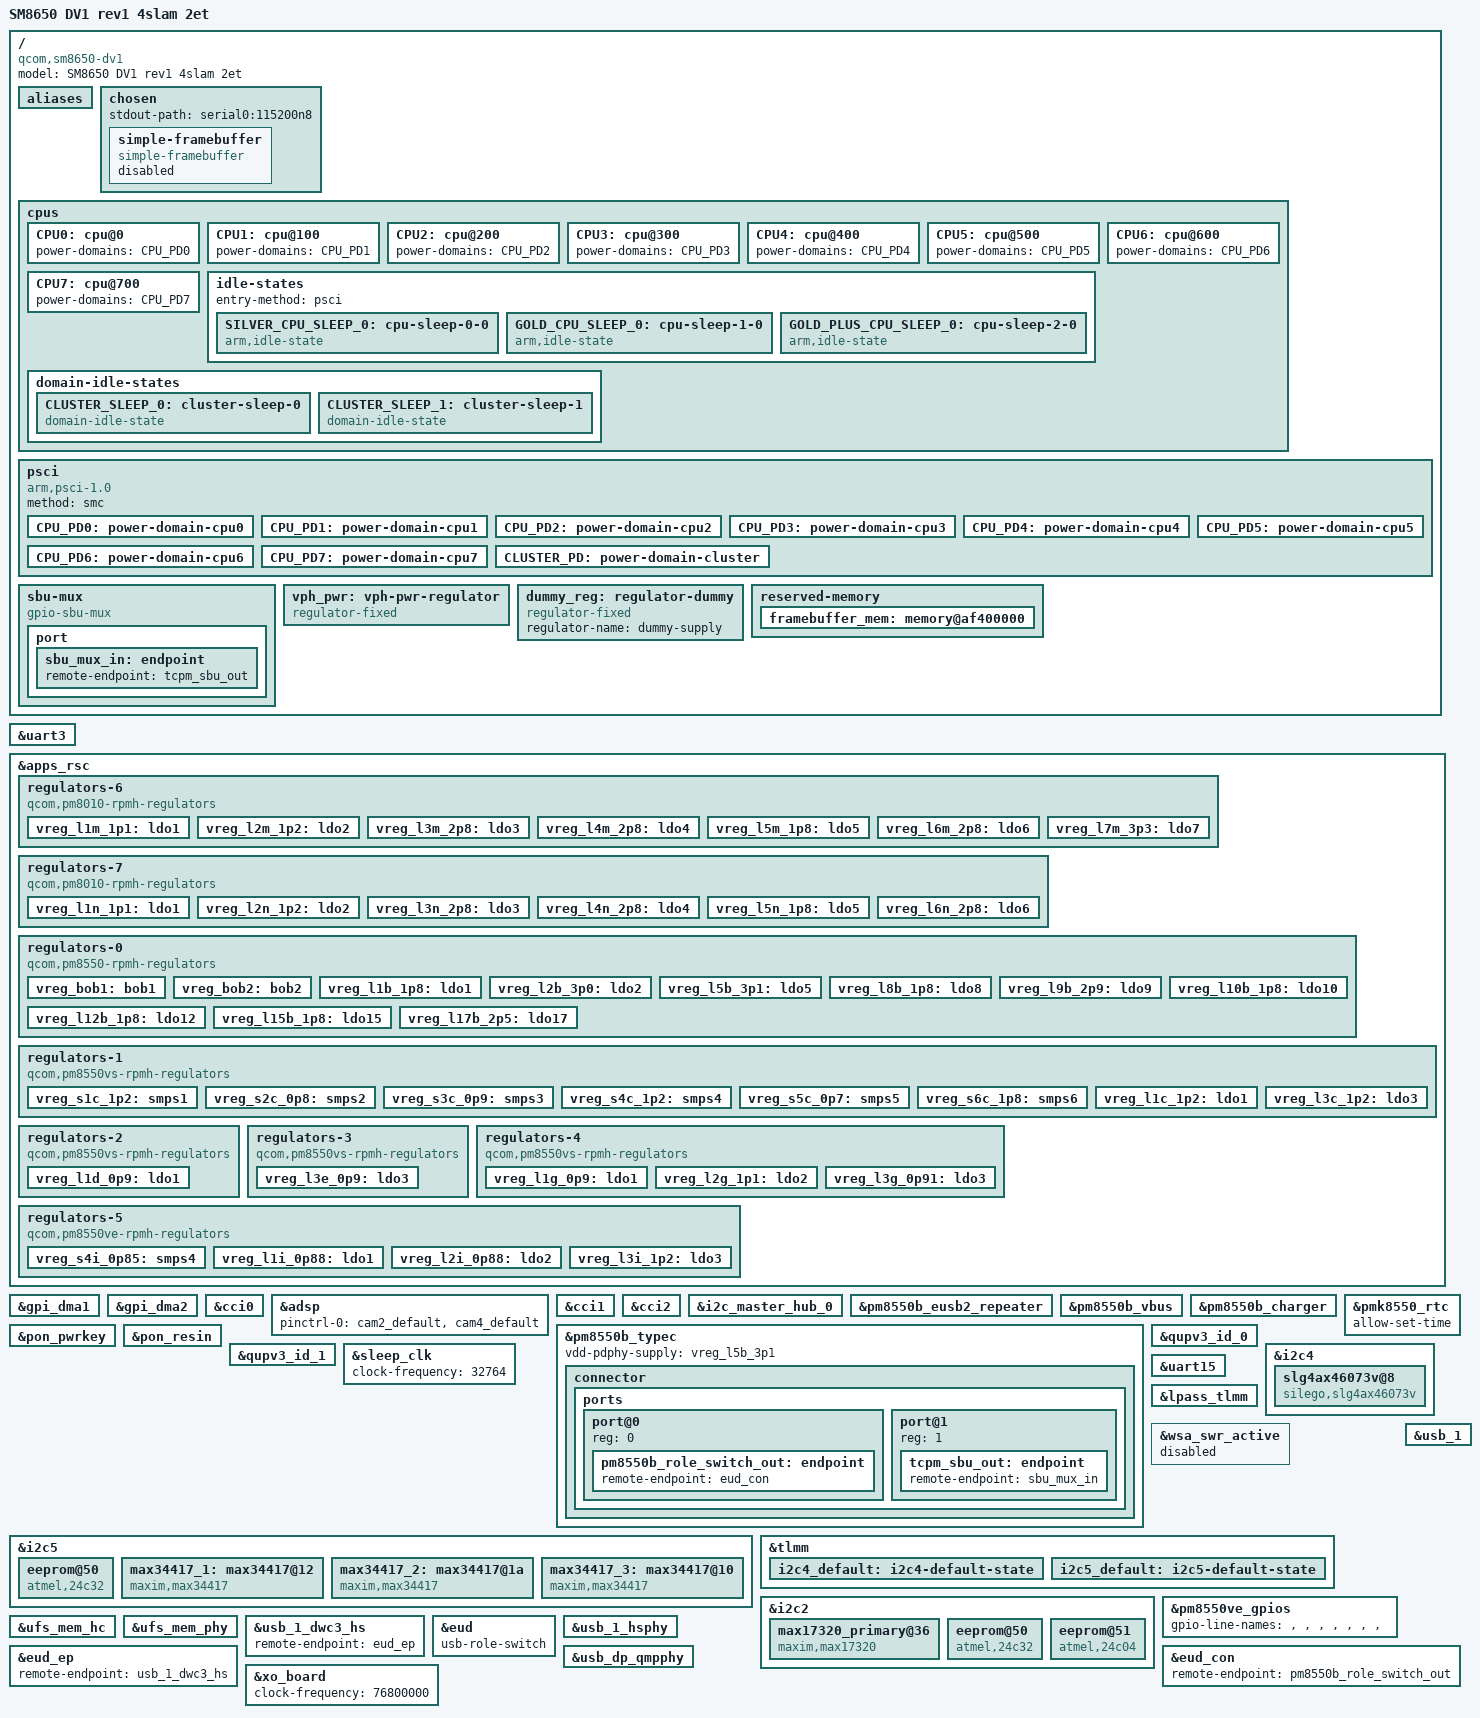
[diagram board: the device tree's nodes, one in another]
/dts-v1/;

#include <dt-bindings/leds/common.h>
#include <dt-bindings/regulator/qcom,rpmh-regulator.h>
#include <dt-bindings/phy/phy.h>
#include "dt-bindings/usb/pd.h"
#include "sm8650.dtsi"
#include "pm8010.dtsi"
#include "pm8550.dtsi"
#include "pm8550b.dtsi"
#include "pm8550vs.dtsi"
#define PMK8550VE_SID 8
#include "pm8550ve.dtsi"
#include "pmk8550.dtsi"
#include "sm8650-el2.dtsi"

/ {
	model = "SM8650 DV1 rev1 4slam 2et";
	compatible = "qcom,sm8650-dv1", "qcom,sm8650";

	aliases {
		serial0 = &uart15;
		serial1 = &uart14;
		serial2 = &uart3;
	};

	chosen {
		stdout-path = "serial0:115200n8";

		simple-framebuffer {
			compatible = "simple-framebuffer";
			width = <4320>;
			height = <2160>;
			stride = <(4320 * 4)>;
			format = "a8r8g8b8";
			memory-region = <&framebuffer_mem>;
			status = "disabled";
		};
	};	

	cpus {

		CPU0: cpu@0 {
			power-domains = <&CPU_PD0>;
			power-domain-names = "psci";
		};

		CPU1: cpu@100 {
			power-domains = <&CPU_PD1>;
			power-domain-names = "psci";
		};

		CPU2: cpu@200 {
			power-domains = <&CPU_PD2>;
			power-domain-names = "psci";
		};

		CPU3: cpu@300 {
			power-domains = <&CPU_PD3>;
			power-domain-names = "psci";
		};

		CPU4: cpu@400 {
			power-domains = <&CPU_PD4>;
			power-domain-names = "psci";
		};

		CPU5: cpu@500 {
			power-domains = <&CPU_PD5>;
			power-domain-names = "psci";
		};

		CPU6: cpu@600 {
			power-domains = <&CPU_PD6>;
			power-domain-names = "psci";
		};

		CPU7: cpu@700 {
			power-domains = <&CPU_PD7>;
			power-domain-names = "psci";
		};

		idle-states {
			entry-method = "psci";

			SILVER_CPU_SLEEP_0: cpu-sleep-0-0 {
				compatible = "arm,idle-state";
				idle-state-name = "silver-rail-power-collapse";
				arm,psci-suspend-param = <0x40000004>;
				entry-latency-us = <550>;
				exit-latency-us = <750>;
				min-residency-us = <6700>;
				local-timer-stop;
			};

			GOLD_CPU_SLEEP_0: cpu-sleep-1-0 {
				compatible = "arm,idle-state";
				idle-state-name = "gold-rail-power-collapse";
				arm,psci-suspend-param = <0x40000004>;
				entry-latency-us = <600>;
				exit-latency-us = <1300>;
				min-residency-us = <8136>;
				local-timer-stop;
			};

			GOLD_PLUS_CPU_SLEEP_0: cpu-sleep-2-0 {
				compatible = "arm,idle-state";
				idle-state-name = "gold-plus-rail-power-collapse";
				arm,psci-suspend-param = <0x40000004>;
				entry-latency-us = <500>;
				exit-latency-us = <1350>;
				min-residency-us = <7480>;
				local-timer-stop;
			};
		};

		domain-idle-states {
			CLUSTER_SLEEP_0: cluster-sleep-0 {
				compatible = "domain-idle-state";
				arm,psci-suspend-param = <0x41000044>;
				entry-latency-us = <750>;
				exit-latency-us = <2350>;
				min-residency-us = <9144>;
			};

			CLUSTER_SLEEP_1: cluster-sleep-1 {
				compatible = "domain-idle-state";
				arm,psci-suspend-param = <0x4100c344>;
				entry-latency-us = <2800>;
				exit-latency-us = <4400>;
				min-residency-us = <10150>;
			};
		};
	};

	psci {
		compatible = "arm,psci-1.0";
		method = "smc";

		CPU_PD0: power-domain-cpu0 {
			#power-domain-cells = <0>;
			power-domains = <&CLUSTER_PD>;
			domain-idle-states = <&SILVER_CPU_SLEEP_0>;
		};

		CPU_PD1: power-domain-cpu1 {
			#power-domain-cells = <0>;
			power-domains = <&CLUSTER_PD>;
			domain-idle-states = <&SILVER_CPU_SLEEP_0>;
		};

		CPU_PD2: power-domain-cpu2 {
			#power-domain-cells = <0>;
			power-domains = <&CLUSTER_PD>;
			domain-idle-states = <&SILVER_CPU_SLEEP_0>;
		};

		CPU_PD3: power-domain-cpu3 {
			#power-domain-cells = <0>;
			power-domains = <&CLUSTER_PD>;
			domain-idle-states = <&GOLD_CPU_SLEEP_0>;
		};

		CPU_PD4: power-domain-cpu4 {
			#power-domain-cells = <0>;
			power-domains = <&CLUSTER_PD>;
			domain-idle-states = <&GOLD_CPU_SLEEP_0>;
		};

		CPU_PD5: power-domain-cpu5 {
			#power-domain-cells = <0>;
			power-domains = <&CLUSTER_PD>;
			domain-idle-states = <&GOLD_CPU_SLEEP_0>;
		};

		CPU_PD6: power-domain-cpu6 {
			#power-domain-cells = <0>;
			power-domains = <&CLUSTER_PD>;
			domain-idle-states = <&GOLD_CPU_SLEEP_0>;
		};

		CPU_PD7: power-domain-cpu7 {
			#power-domain-cells = <0>;
			power-domains = <&CLUSTER_PD>;
			domain-idle-states = <&GOLD_PLUS_CPU_SLEEP_0>;
		};

		CLUSTER_PD: power-domain-cluster {
			#power-domain-cells = <0>;
			domain-idle-states = <&CLUSTER_SLEEP_0>,
					     <&CLUSTER_SLEEP_1>;
		};
	};

	sbu-mux {
		compatible = "gpio-sbu-mux";

		enable-gpios = <&tlmm 86 GPIO_ACTIVE_LOW>;
		select-gpios = <&tlmm 82 GPIO_ACTIVE_HIGH>;

		mode-switch;
		orientation-switch;

		port {
			sbu_mux_in: endpoint {
				remote-endpoint = <&tcpm_sbu_out>;
			};
		};

		// XXX: needs VREG_L05B_3P1, VREG_BOB2
	};

	vph_pwr: vph-pwr-regulator {
		compatible = "regulator-fixed";

		regulator-name = "vph_pwr";
		regulator-min-microvolt = <3700000>;
		regulator-max-microvolt = <3700000>;

		regulator-always-on;
		regulator-boot-on;
	};



	dummy_reg: regulator-dummy {
		compatible = "regulator-fixed";
		regulator-name = "dummy-supply";
	};

	reserved-memory {
                ranges;

                framebuffer_mem: memory@af400000 {
			reg = <0 0xaf400000 0 0x03000000>;
                        no-map;
                };
        };

};

&uart3 {
	status = "okay";
};


&apps_rsc {
    regulators-6 {
        vdd-l6-supply = <&vreg_bob2>;
    };
    regulators-7 {
        vdd-l6-supply = <&vreg_bob2>;
    };
};


&apps_rsc {
	regulators-0 {
		compatible = "qcom,pm8550-rpmh-regulators";

		vdd-bob1-supply = <&vph_pwr>;
		vdd-bob2-supply = <&vph_pwr>;
		vdd-l1-l4-l10-supply = <&vreg_s6c_1p8>;
		vdd-l2-l13-l14-supply = <&vreg_bob1>;
		vdd-l3-supply = <&vreg_s1c_1p2>;
		vdd-l5-l16-supply = <&vreg_bob1>;
		vdd-l8-l9-supply = <&vreg_bob1>;
		vdd-l12-supply = <&vreg_s6c_1p8>;
		vdd-l15-supply = <&vreg_s6c_1p8>;
		vdd-l17-supply = <&vreg_bob2>;

		qcom,pmic-id = "b";

		vreg_bob1: bob1 {
			regulator-name = "vreg_bob1";
			regulator-min-microvolt = <3296000>; // note: min is 3008000, init is 3296000
			regulator-max-microvolt = <3960000>;
			regulator-initial-mode = <RPMH_REGULATOR_MODE_HPM>;
		};

		vreg_bob2: bob2 {
			regulator-name = "vreg_bob2";
			regulator-min-microvolt = <2720000>; // note: min is 2704000, init is 2720000
			regulator-max-microvolt = <3008000>;
			regulator-initial-mode = <RPMH_REGULATOR_MODE_HPM>;

			regulator-always-on; // XXX USB HS, SBU MUX
		};

		vreg_l1b_1p8: ldo1 {
			regulator-name = "vreg_l1b_1p8";
			regulator-min-microvolt = <1800000>;
			regulator-max-microvolt = <1800000>;
			regulator-initial-mode = <RPMH_REGULATOR_MODE_HPM>;

			regulator-always-on; // XXX sensors
		};

		vreg_l2b_3p0: ldo2 {
			regulator-name = "vreg_l2b_3p0";
			regulator-min-microvolt = <3008000>;
			regulator-max-microvolt = <3008000>;
			regulator-initial-mode = <RPMH_REGULATOR_MODE_HPM>;

			regulator-always-on; // XXX sensors
		};

		vreg_l5b_3p1: ldo5 {
			regulator-name = "vreg_l5b_3p1";
			regulator-min-microvolt = <3104000>;
			regulator-max-microvolt = <3104000>;
			regulator-initial-mode = <RPMH_REGULATOR_MODE_HPM>;
			regulator-allow-set-load;
			regulator-allowed-modes = <RPMH_REGULATOR_MODE_LPM
						   RPMH_REGULATOR_MODE_HPM>;
			regulator-always-on; // XXX SBU MUX
		};

		vreg_l8b_1p8: ldo8 {
			regulator-name = "vreg_l8b_1p8";
			regulator-min-microvolt = <1800000>;
			regulator-max-microvolt = <1800000>;
			regulator-initial-mode = <RPMH_REGULATOR_MODE_HPM>;
			regulator-allow-set-load;
			regulator-allowed-modes = <RPMH_REGULATOR_MODE_LPM
						   RPMH_REGULATOR_MODE_HPM>;
		};

		vreg_l9b_2p9: ldo9 {
			regulator-name = "vreg_l9b_2p9";
			regulator-min-microvolt = <2960000>;
			regulator-max-microvolt = <2960000>;
			regulator-initial-mode = <RPMH_REGULATOR_MODE_HPM>;
			regulator-allow-set-load;
			regulator-allowed-modes = <RPMH_REGULATOR_MODE_LPM
						   RPMH_REGULATOR_MODE_HPM>;
		};

		vreg_l10b_1p8: ldo10 {
			regulator-name = "vreg_l10b_1p8";
			regulator-min-microvolt = <1800000>;
			regulator-max-microvolt = <1800000>;
			regulator-initial-mode = <RPMH_REGULATOR_MODE_HPM>;

			regulator-always-on; // XXX DMIC
		};

		vreg_l12b_1p8: ldo12 {
			regulator-name = "vreg_l12b_1p8";
			regulator-min-microvolt = <1800000>;
			regulator-max-microvolt = <1800000>;
			regulator-initial-mode = <RPMH_REGULATOR_MODE_HPM>;
			regulator-allow-set-load;
			regulator-allowed-modes = <RPMH_REGULATOR_MODE_LPM
						   RPMH_REGULATOR_MODE_HPM>;
		};

		vreg_l15b_1p8: ldo15 {
			regulator-name = "vreg_l15b_1p8";
			regulator-min-microvolt = <1800000>;
			regulator-max-microvolt = <1800000>;
			regulator-initial-mode = <RPMH_REGULATOR_MODE_HPM>;
			regulator-allow-set-load;
			regulator-allowed-modes = <RPMH_REGULATOR_MODE_LPM
						   RPMH_REGULATOR_MODE_HPM>;
			regulator-always-on; // XXX: 1.8V pull ups
		};

		vreg_l17b_2p5: ldo17 {
			regulator-name = "vreg_l17b_2p5";
			regulator-min-microvolt = <2504000>;
			regulator-max-microvolt = <2504000>;
			regulator-initial-mode = <RPMH_REGULATOR_MODE_HPM>;
			regulator-allow-set-load;
			regulator-allowed-modes = <RPMH_REGULATOR_MODE_LPM
						   RPMH_REGULATOR_MODE_HPM>;
		};
	};

	regulators-1 {
		compatible = "qcom,pm8550vs-rpmh-regulators";

		vdd-l1-supply = <&vreg_s1c_1p2>;
		vdd-l3-supply = <&vreg_s1c_1p2>;
		vdd-s1-supply = <&vph_pwr>;
		vdd-s2-supply = <&vph_pwr>;
		vdd-s3-supply = <&vph_pwr>;
		vdd-s4-supply = <&vph_pwr>;
		vdd-s5-supply = <&vph_pwr>;
		vdd-s6-supply = <&vph_pwr>;

		qcom,pmic-id = "c";

		vreg_s1c_1p2: smps1 {
			regulator-name = "vreg_s1c_1p2";
			regulator-min-microvolt = <1224000>;
			regulator-max-microvolt = <1348000>;
			// init 1256000
			regulator-initial-mode = <RPMH_REGULATOR_MODE_HPM>;

			regulator-always-on; // USB, UFS?
		};

		vreg_s2c_0p8: smps2 {
			regulator-name = "vreg_s2c_0p8";
			regulator-min-microvolt = <500000>;
			regulator-max-microvolt = <1036000>;
			// init 852000
			regulator-initial-mode = <RPMH_REGULATOR_MODE_HPM>;
		};

		vreg_s3c_0p9: smps3 {
			regulator-name = "vreg_s3c_0p9";
			regulator-min-microvolt = <904000>;
			regulator-max-microvolt = <1064000>;
			// init 976000
			regulator-initial-mode = <RPMH_REGULATOR_MODE_HPM>;
		};

		vreg_s4c_1p2: smps4 {
			regulator-name = "vreg_s4c_1p2";
			regulator-min-microvolt = <1200000>;
			regulator-max-microvolt = <1280000>;
			// init 1224000
			regulator-initial-mode = <RPMH_REGULATOR_MODE_HPM>;
		};

		vreg_s5c_0p7: smps5 {
			regulator-name = "vreg_s5c_0p7";
			regulator-min-microvolt = <300000>;
			regulator-max-microvolt = <900000>;
			// init 752000
			regulator-initial-mode = <RPMH_REGULATOR_MODE_HPM>;
		};

		vreg_s6c_1p8: smps6 {
			regulator-name = "vreg_s6c_1p8";
			regulator-min-microvolt = <1856000>;
			regulator-max-microvolt = <2000000>;
			// init 1856000
			regulator-initial-mode = <RPMH_REGULATOR_MODE_HPM>;
		};

		vreg_l1c_1p2: ldo1 {
			regulator-name = "vreg_l1c_1p2";
			regulator-min-microvolt = <1200000>; // note: min 1100000
			regulator-max-microvolt = <1200000>;
			regulator-initial-mode = <RPMH_REGULATOR_MODE_HPM>;
		};

		vreg_l3c_1p2: ldo3 {
			regulator-name = "vreg_l3c_1p2";
			regulator-min-microvolt = <1200000>;
			regulator-max-microvolt = <1200000>;
			regulator-initial-mode = <RPMH_REGULATOR_MODE_HPM>;
			regulator-allow-set-load;
			regulator-allowed-modes = <RPMH_REGULATOR_MODE_LPM
						   RPMH_REGULATOR_MODE_HPM>;
			regulator-always-on; // XXX: 1.2V pull ups
		};
	};

	regulators-2 {
		compatible = "qcom,pm8550vs-rpmh-regulators";
		qcom,pmic-id = "d";

		vdd-l1-supply = <&vreg_s3c_0p9>;

		vreg_l1d_0p9: ldo1 {
			regulator-name = "vreg_l1d_0p9";
			regulator-min-microvolt = <912000>; // note: min 880000
			regulator-max-microvolt = <920000>;
			regulator-initial-mode = <RPMH_REGULATOR_MODE_HPM>;
			regulator-allow-set-load;
			regulator-allowed-modes = <RPMH_REGULATOR_MODE_LPM
						   RPMH_REGULATOR_MODE_HPM>;
		};
	};

	regulators-3 {
		compatible = "qcom,pm8550vs-rpmh-regulators";

		vdd-l3-supply = <&vreg_s3c_0p9>;

		qcom,pmic-id = "e";

		vreg_l3e_0p9: ldo3 {
			regulator-name = "vreg_l3e_0p9";
			regulator-min-microvolt = <880000>;
			regulator-max-microvolt = <920000>;
			regulator-initial-mode = <RPMH_REGULATOR_MODE_HPM>;
			regulator-allow-set-load;
			regulator-allowed-modes = <RPMH_REGULATOR_MODE_LPM
						   RPMH_REGULATOR_MODE_HPM>;
		};
	};

	regulators-4 {
		compatible = "qcom,pm8550vs-rpmh-regulators";

		vdd-l1-supply = <&vreg_s3c_0p9>;
		vdd-l2-supply = <&vreg_s1c_1p2>;
		vdd-l3-supply = <&vreg_s3c_0p9>;

		qcom,pmic-id = "g";

		vreg_l1g_0p9: ldo1 {
			regulator-name = "vreg_l1g_0p9";
			regulator-min-microvolt = <912000>;
			regulator-max-microvolt = <920000>;
			regulator-initial-mode = <RPMH_REGULATOR_MODE_HPM>;
			// QLINK ?
		};

		vreg_l2g_1p1: ldo2 {
			regulator-name = "vreg_l2g_1p1";
			regulator-min-microvolt = <1104000>;
			regulator-max-microvolt = <1104000>;
			regulator-initial-mode = <RPMH_REGULATOR_MODE_HPM>;
		};

		vreg_l3g_0p91: ldo3 {
			regulator-name = "vreg_l3g_0p91";
			regulator-min-microvolt = <880000>;
			regulator-max-microvolt = <912000>;
			regulator-initial-mode = <RPMH_REGULATOR_MODE_HPM>;
		};
	};

	regulators-5 {
		compatible = "qcom,pm8550ve-rpmh-regulators";

		vdd-l1-supply = <&vreg_s3c_0p9>;
		vdd-l2-supply = <&vreg_s3c_0p9>;
		vdd-l3-supply = <&vreg_s1c_1p2>;
		vdd-s4-supply = <&vph_pwr>;

		qcom,pmic-id = "i";

		vreg_s4i_0p85: smps4 {
			regulator-name = "vreg_s4i_0p85";
			regulator-min-microvolt = <852000>;
			regulator-max-microvolt = <1004000>;
			// init 852000
			regulator-initial-mode = <RPMH_REGULATOR_MODE_HPM>;
		};

		vreg_l1i_0p88: ldo1 {
			regulator-name = "vreg_l1i_0p88";
			regulator-min-microvolt = <880000>;
			regulator-max-microvolt = <912000>;
			regulator-initial-mode = <RPMH_REGULATOR_MODE_HPM>;
			regulator-allow-set-load;
			regulator-allowed-modes = <RPMH_REGULATOR_MODE_LPM
						   RPMH_REGULATOR_MODE_HPM>;
		};

		vreg_l2i_0p88: ldo2 {
			regulator-name = "vreg_l2i_0p88";
			regulator-min-microvolt = <880000>;
			regulator-max-microvolt = <912000>;
			regulator-initial-mode = <RPMH_REGULATOR_MODE_HPM>;
			regulator-allow-set-load;
			regulator-allowed-modes = <RPMH_REGULATOR_MODE_LPM
						   RPMH_REGULATOR_MODE_HPM>;

			//regulator-always-on; // CSI PHY
		};

		vreg_l3i_1p2: ldo3 {
			regulator-name = "vreg_l3i_1p2";
			regulator-min-microvolt = <1200000>;
			regulator-max-microvolt = <1200000>;
			regulator-initial-mode = <RPMH_REGULATOR_MODE_HPM>;
			regulator-allow-set-load;
			regulator-allowed-modes = <RPMH_REGULATOR_MODE_LPM
						   RPMH_REGULATOR_MODE_HPM>;

			//regulator-always-on; // CSI PHY
		};
	};

	regulators-6 {
		compatible = "qcom,pm8010-rpmh-regulators";
		qcom,pmic-id = "m";

		vdd-l1-l2-supply = <&vreg_s1c_1p2>;
		vdd-l3-l4-supply = <&vreg_bob2>;
		vdd-l5-supply = <&vreg_s6c_1p8>;
		vdd-l6-supply = <&vreg_bob1>;
		vdd-l7-supply = <&vreg_bob1>;

		vreg_l1m_1p1: ldo1 {
			regulator-name = "vreg_l1m_1p1";
			regulator-min-microvolt = <1104000>;
			regulator-max-microvolt = <1104000>;
			regulator-initial-mode = <RPMH_REGULATOR_MODE_HPM>;
			regulator-allow-set-load;
			regulator-allowed-modes = <RPMH_REGULATOR_MODE_LPM
						   RPMH_REGULATOR_MODE_HPM>;
		};

		vreg_l2m_1p2: ldo2 {
			regulator-name = "vreg_l2m_1p2";
			regulator-min-microvolt = <1200000>;
			regulator-max-microvolt = <1200000>;
			regulator-initial-mode = <RPMH_REGULATOR_MODE_HPM>;
			regulator-allow-set-load;
			regulator-allowed-modes = <RPMH_REGULATOR_MODE_LPM
						   RPMH_REGULATOR_MODE_HPM>;
		};

		vreg_l3m_2p8: ldo3 {
			regulator-name = "vreg_l3m_2p8";
			regulator-min-microvolt = <2800000>;
			regulator-max-microvolt = <2800000>;
			regulator-initial-mode = <RPMH_REGULATOR_MODE_HPM>;
		};

		vreg_l4m_2p8: ldo4 {
			regulator-name = "vreg_l4m_2p8";
			regulator-min-microvolt = <2800000>;
			regulator-max-microvolt = <2800000>;
			regulator-initial-mode = <RPMH_REGULATOR_MODE_HPM>;
		};

		vreg_l5m_1p8: ldo5 {
			regulator-name = "vreg_l5m_1p8";
			regulator-min-microvolt = <1800000>;
			regulator-max-microvolt = <1800000>;
			regulator-initial-mode = <RPMH_REGULATOR_MODE_HPM>;
		};

		vreg_l6m_2p8: ldo6 {
			regulator-name = "vreg_l6m_2p8";
			regulator-min-microvolt = <2800000>;
			regulator-max-microvolt = <2800000>;
			regulator-initial-mode = <RPMH_REGULATOR_MODE_HPM>;
		};

		vreg_l7m_3p3: ldo7 {
			regulator-name = "vreg_l7m_3p3";
			regulator-min-microvolt = <3304000>;
			regulator-max-microvolt = <3304000>;
			regulator-initial-mode = <RPMH_REGULATOR_MODE_HPM>;

			regulator-always-on;
		};
	};

	regulators-7 {
		compatible = "qcom,pm8010-rpmh-regulators";
		qcom,pmic-id = "n";

		vdd-l1-l2-supply = <&vreg_s1c_1p2>;
		vdd-l3-l4-supply = <&vreg_bob2>;
		vdd-l5-supply = <&vreg_s6c_1p8>;
		vdd-l6-supply = <&vreg_bob1>;

		vreg_l1n_1p1: ldo1 {
			regulator-name = "vreg_l1n_1p1";
			regulator-min-microvolt = <1104000>;
			regulator-max-microvolt = <1104000>;
			regulator-initial-mode = <RPMH_REGULATOR_MODE_HPM>;
			regulator-allow-set-load;
			regulator-allowed-modes = <RPMH_REGULATOR_MODE_LPM
						   RPMH_REGULATOR_MODE_HPM>;
		};

		vreg_l2n_1p2: ldo2 {
			regulator-name = "vreg_l2n_1p2";
			regulator-min-microvolt = <1200000>;
			regulator-max-microvolt = <1200000>;
			regulator-initial-mode = <RPMH_REGULATOR_MODE_HPM>;
			regulator-allow-set-load;
			regulator-allowed-modes = <RPMH_REGULATOR_MODE_LPM
						   RPMH_REGULATOR_MODE_HPM>;
		};

		vreg_l3n_2p8: ldo3 {
			regulator-name = "vreg_l3n_2p8";
			regulator-min-microvolt = <2800000>;
			regulator-max-microvolt = <2800000>;
			regulator-initial-mode = <RPMH_REGULATOR_MODE_HPM>;
		};

		vreg_l4n_2p8: ldo4 {
			regulator-name = "vreg_l4n_2p8";
			regulator-min-microvolt = <2800000>;
			regulator-max-microvolt = <2800000>;
			regulator-initial-mode = <RPMH_REGULATOR_MODE_HPM>;
		};

		vreg_l5n_1p8: ldo5 {
			regulator-name = "vreg_l5n_1p8";
			regulator-min-microvolt = <1800000>;
			regulator-max-microvolt = <1800000>;
			regulator-initial-mode = <RPMH_REGULATOR_MODE_HPM>;
		};

		vreg_l6n_2p8: ldo6 {
			regulator-name = "vreg_l6n_2p8";
			regulator-min-microvolt = <2800000>;
			regulator-max-microvolt = <2800000>;
			regulator-initial-mode = <RPMH_REGULATOR_MODE_HPM>;
		};
	};
};

&gpi_dma1 {
	status = "okay";
};

&gpi_dma2 {
	status = "okay";
};

&cci0 {
	status = "okay";
};

// ADSP controls eye tracking cameras
&adsp {
	// AON CAM ADSP TEST: gpio102/104 to mclk function
	pinctrl-names = "default";
	pinctrl-0 = <&cam2_default &cam4_default>;
};

&cci1 {
	pinctrl-0 = <&cci1_0_default>;
	pinctrl-1 = <&cci1_0_sleep>;
	status = "okay";
};

&cci2 {
	status = "okay";
};


// Master Hub required for Hub 7 and 8
&i2c_master_hub_0 {
	status = "okay";
};


&pm8550b_eusb2_repeater {
	vdd18-supply = <&vreg_l15b_1p8>;
	vdd3-supply = <&vreg_l5b_3p1>;
};

&pm8550b_vbus {
	status = "okay";
};

&pm8550b_typec {
	status = "okay";

	vdd-pdphy-supply = <&vreg_l5b_3p1>;

	connector {
		power-role = "dual";
		data-role = "dual";
		try-power-role = "sink";
		
		source-pdos = <PDO_FIXED(5000, 3000, PDO_FIXED_DUAL_ROLE | PDO_FIXED_DATA_SWAP | PDO_FIXED_USB_COMM)>;
		
		//sink-pdos needs to have 5000mV entry first otherwise will not probe
		sink-pdos = <PDO_FIXED(5000, 3000, PDO_FIXED_DUAL_ROLE | PDO_FIXED_DATA_SWAP | PDO_FIXED_USB_COMM)>,
                    <PDO_FIXED(9000, 3000, PDO_FIXED_DUAL_ROLE | PDO_FIXED_DATA_SWAP | PDO_FIXED_USB_COMM)>,
                    <PDO_FIXED(12000, 3000, PDO_FIXED_DUAL_ROLE | PDO_FIXED_DATA_SWAP | PDO_FIXED_USB_COMM)>,
                    <PDO_FIXED(15000, 3000, PDO_FIXED_DUAL_ROLE | PDO_FIXED_DATA_SWAP | PDO_FIXED_USB_COMM)>;

		op-sink-microwatt = <15000000>;

		ports {
			#address-cells = <1>;
			#size-cells = <0>;

			port@0 {
				reg = <0>;

				pm8550b_role_switch_out: endpoint {
					remote-endpoint = <&eud_con>;
				};
			};

			port@1 {
				reg = <1>;

				tcpm_sbu_out: endpoint {
					remote-endpoint = <&sbu_mux_in>;
				};
			};

#if 0
			port@2 {
				reg = <2>;

				dp_mode_out: endpoint {
					remote-endpoint = <&dp_mode>;
				};
			};


			port@1 {
				reg = <1>;

				pm8550b_typec_mux_out: endpoint {
					remote-endpoint = <&usb_1_qmpphy_typec_mux_in>;
				};
			};
#endif
		};
	};

};

&pm8550b_charger {
	status = "okay";
	qph1-charge-current-max = <1200000>;
	qph2-charge-current-max = <2700000>;
};

&pmk8550_rtc {
	status = "okay";
	allow-set-time;
};

&pon_pwrkey {
	status = "okay";
};

&pon_resin {
	linux,code = <KEY_VOLUMEDOWN>;
	disable-wake-source;
	status = "okay";
};


&qupv3_id_0 {
	status = "okay";
};

&qupv3_id_1 {
	status = "okay";
};



&sleep_clk {
	clock-frequency = <32764>;
};



&i2c4 {
	status = "okay";
	
    /* FAN_I2C */
	slg4ax46073v@8 {
		compatible = "silego,slg4ax46073v";
		reg = <0x08>;
		#address-cells = <1>;
		#size-cells = <0>;

		//vdd-fan-1-supply = <&VBATT_2S>; not modeled in dts
		fan-alert-gpios = <&tlmm 174 GPIO_ACTIVE_HIGH>;
		en-gpio = <&tlmm 138 GPIO_ACTIVE_HIGH>;
		// bp pin removed in ev1

		status = "okay";
	};

};

&i2c5 {
	status = "okay";

};

&uart15 {
	status = "okay";
};

&lpass_tlmm {
	status = "okay";
};

// Disable Soundwire
&wsa_swr_active {
	status = "disabled";
};

&tlmm {
	// TODO verify reserved pins for 8650
	// qcom,gpios-reserved = <36 37 38 39>;
	gpio-line-names =
		// GPIO000 - GPIO015
		"",  "",  "",  "",  "",  "",  "",  "fpga_rst",  "",  "",  "",  "nrf_time_sync",  "",  "",  "",  "",
		// GPIO016 - GPIO031
		"",  "",  "",  "",  "",  "",  "",  "",  "",  "",  "",  "",  "",  "",  "",  "",
		// GPIO032 - GPIO047
		"",  "",  "",  "fpga_spi_cs",  "",  "",  "",  "fpga_crst",  "",  "",  "",  "",  "",  "",  "",  "",
		// GPIO048 - GPIO063
		"",  "",  "nrf_swdio",  "nrf_swclk",  "",  "",  "",  "",  "fpga_cam0_strobe",  "fpga_cam1_strobe",  "",  "",  "",  "",  "",  "",
		// GPIO064 - GPIO079
		"",  "",  "",  "",  "",  "",  "",  "",  "",  "",  "",  "",  "",  "",  "",  "",
		// GPIO080 - GPIO095
		"",  "",  "",  "",  "",  "",  "",  "",  "",  "",  "",  "",  "",  "",  "",  "",
		// GPIO096 - GPIO111
		"",  "",  "",  "",  "",  "",  "",  "",  "",  "",  "",  "",  "",  "",  "fpga_cam1_frame_sync",  "",
		// GPIO112 - GPIO127
		"",  "",  "",  "",  "",  "",  "",  "",  "",  "",  "",  "",  "fpga_cam0_frame_sync",  "",  "",  "",
		// GPIO128 - GPIO143
		"",  "",  "",  "",  "",  "",  "",  "",  "",  "",  "",  "",  "",  "",  "",  "",
		// GPIO144 - GPIO159
		"",  "",  "",  "",  "",  "",  "",  "",  "",  "",  "",  "fpga_cdone",  "",  "",  "fpga_cready",  "",
		// GPIO160 - GPIO175
		"",  "",  "te2_left",  "",  "nrf_reset",  "",  "",  "",  "",  "",  "",  "",  "",  "",  "",  "",
		// GPIO176 - GPIO189
		"",  "",  "te2_right",  "",  "", "", "", "", "", "", "", "", "", "";
};

&i2c5 {
    // BOOT EEPROM
    eeprom@50 {
        compatible  = "atmel,24c32";
        status      = "okay";
        label		= "core_eeprom";
        reg         = <0x50>;
		pagesize    = <32>;
		size        = <4096>;
		address-width = <16>;
        wp-gpios = <&tlmm 78 GPIO_ACTIVE_HIGH>;
        vcc-supply  = <&vreg_l15b_1p8>;
    };

    max34417_1: max34417@12 {
        compatible = "maxim,max34417";
        reg = <0x12>;
        maxim,sense-resistor = <1>;
        vdd-supply = <&vreg_l2b_3p0>;
        vio-supply = <&vreg_l15b_1p8>;
        status = "okay";

        // CH 1 : Kryo APC0 Cores
        // CH 2 : Kryo APC2 Cores
        // CH 3 : Kryo APC1 Cores
        // CH 4 : Tensor Processor – NSP1
        // Note: both 1.8 and 3.0V rails are always on for other sensors
    };

    max34417_2: max34417@1a {
        compatible = "maxim,max34417";
        reg = <0x1a>;
        maxim,sense-resistor = <1>;
        vdd-supply = <&vreg_l2b_3p0>;
        vio-supply = <&vreg_l15b_1p8>;
        status = "okay";

        // CH 1 : GFX Power
        // CH 2 : Tensor Processor – NSP2
        // CH 3 : Bob Power
        // CH 4 : Unused
        // Note: both 1.8 and 3.0V rails are always on for other sensors
    };

    // TODO enable verr ( varies based on common mode range )
    max34417_3: max34417@10 {
        compatible = "maxim,max34417";
        reg = <0x10>;
        maxim,sense-resistor = <1>;
        vdd-supply = <&vreg_l2b_3p0>;
        vio-supply = <&vreg_l15b_1p8>;
        status = "okay";

        // CH 1 : VPH
        // CH 2 : S6C ~1.9V Subregulation
        // CH 3 : S3C ~1.3V Subregulation
        // CH 4 : S1C ~1V Subregulation
        // Note: both 1.8 and 3.0V rails are always on for other sensors
    }; 
};

// Custom Connector I2C ( Paddle Card )
&i2c2 {
	status = "okay";

	// Southgate/Northgate Primary Built In Battery
	max17320_primary@36 {
		compatible  = "maxim,max17320";
		status		= "okay";
		reg         = <0x36>;
		nvm_reg     = /bits/ 8 <0x0b>;
		rsense      = <25>;      /* 100's of microOhms */
	};

	// Southgate/Northgate Secondary Hotswap Battery
	// NOTE This is handled dynamically by northgate_hotswap driver
	// max17320_hotswap@76 {
	//	compatible  = "maxim,max17320";
	//	status		= "okay";
	//	reg         = <0x76>;
	//	nvm_reg     = /bits/ 8 <0x4b>;
	//	rsense      = <25>;      /* 100's of microOhms */
	// };

    // PADDLE EEPROM
    eeprom@50 {
        compatible  = "atmel,24c32";
        status      = "okay";
		label		= "strap_eeprom";
        reg         = <0x50>;
        //wp-gpios = <&tlmm 78 GPIO_ACTIVE_HIGH>;
        vcc-supply  = <&vreg_l15b_1p8>;
    };

	// PADDLE EEPROM - 256 Bytes on 0x51 added in EV3.3
	eeprom@51 {
		compatible  = "atmel,24c04";
		status      = "okay";
		label       = "strap_v2_eeprom";
		reg         = <0x51>;
		vcc-supply  = <&vreg_l15b_1p8>;
	};


};


&pm8550ve_gpios {
	gpio-line-names =
		// GPIO01 - GPIO08
		"",  "",  "",  "",  "",  "",  "",  "";
};



// nRF Pins
&tlmm {
	i2c4_default: i2c4-default-state {
		pins = "gpio48", "gpio49";
		function = "gpio";
		drive-strength = <2>;
		bias-pull-up;
	};

	i2c5_default: i2c5-default-state {
		pins = "gpio52", "gpio53";
		function = "gpio";
		drive-strength = <2>;
		bias-pull-up;
	};
};

&ufs_mem_hc {
	reset-gpios = <&tlmm 210 GPIO_ACTIVE_LOW>;

	vcc-supply = <&vreg_l17b_2p5>;
	vcc-max-microamp = <1300000>;
	vccq-supply = <&vreg_l1c_1p2>;
	vccq-max-microamp = <1200000>;

	status = "okay";
};

&ufs_mem_phy {
	vdda-phy-supply = <&vreg_l1d_0p9>;
	vdda-pll-supply = <&vreg_l3i_1p2>;

	status = "okay";
};

&usb_1 {
	dr_mode = "otg";
	usb-role-switch;
	status = "okay";
};

&usb_1_dwc3_hs {
	remote-endpoint = <&eud_ep>;
};

&eud {
	status = "okay";
	usb-role-switch;
};

&eud_con {
	remote-endpoint = <&pm8550b_role_switch_out>;
};

&eud_ep {
	remote-endpoint = <&usb_1_dwc3_hs>;
};

&usb_1_hsphy {
	vdd-supply = <&vreg_l1i_0p88>;
	vdda12-supply = <&vreg_l3i_1p2>;

	phys = <&pm8550b_eusb2_repeater>;

	status = "okay";
};

&usb_dp_qmpphy {
	vdda-phy-supply = <&vreg_l3i_1p2>;
	vdda-pll-supply = <&vreg_l3g_0p91>;

	orientation-switch;

	status = "okay";
};

&xo_board {
	clock-frequency = <76800000>;
};

#if 0
&mdss {
	status = "disabled";
};

&cvp {
	status = "disabled";
};

&dispcc {
	status = "disabled";
};

&camcc {
	status = "disabled";
};

&videocc {
	status = "disabled";
};

&lpass_aoncc {
	status = "disabled";
};

&gpucc {
	status = "disabled";
};

&gmu {
	status = "disabled";
};

&ice {
	status = "disabled";
};

&icp {
	status = "disabled";
};

&lpass_audiocc {
	status = "disabled";
};
#endif

fw_setenv fdt_disable_soc_nodes "clock-controller@af00000,cvp@ab00000,display-subsystem@ae00000,clock-controller@ade0000,icp@ac00000,clock-controller@aaf0000,clock-controller@6e00000,clock-controller@6bc0000,clock-controller@3d90000,gmu@3d6a000,crypto@1d88000"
